# STM32MP21_CM33 register map
File version: 0.4
CPU: CM33 r0p1, little endian, MPU, FPU, vendor SysTick, 8 interrupt priority bits
Registers are 32-bit, read-write, reset 0x0 unless marked. A register's access mark holds for its fields unless they carry their own. Offsets are from the block's base; [hi:lo] are bit positions.

## TIM6 — TIM6 address block description
Base 0x40040000
Same registers: TIM6_S 0x50040000
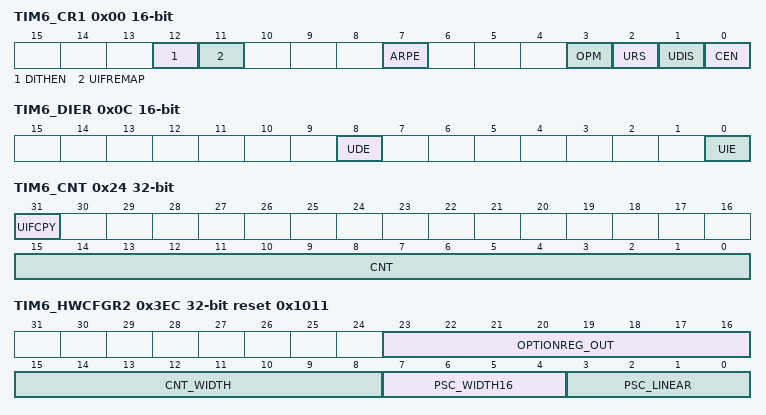
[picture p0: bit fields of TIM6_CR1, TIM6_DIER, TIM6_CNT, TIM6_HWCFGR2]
0x00 TIM6_CR1 16-bit — TIM6 control register 1
  [12] DITHEN — Dithering enable
    0=Dithering disabled; 1=Dithering enabled
  [11] UIFREMAP — UIF status bit remapping
    0=No remapping; 1=Remapping enabled
  [7] ARPE — Auto-reload preload enable
    0=TIMx_ARR register is not buffered; 1=TIMx_ARR register is buffered
  [3] OPM — One-pulse mode
    0=Counter is not stopped at update event; 1=Counter stops counting at the next update event (clearing the CEN bit)
  [2] URS — Update request source
    0=Any of the following events generates an update interrupt or DMA request if enabled; 1=Only counter overflow/underflow generates an update interrupt or DMA request if enabled
  [1] UDIS — Update disable
    0=UEV enabled; 1=UEV disabled
  [0] CEN — Counter enable
    0=Counter disabled; 1=Counter enabled
0x04 TIM6_CR2 16-bit — TIM6 control register 2
  [6:4] MMS — Master mode selection
    0=Reset - the UG bit from the TIMx_EGR register is used as a trigger output (tim_trgo); 1=Enable - the Counter enable signal, tim_cnt_en, is used as a trigger output (tim_trgo); 2=Update - The update event is selected as a trigger output (tim_trgo)
0x0C TIM6_DIER 16-bit — TIM6 DMA/Interrupt enable register
  [8] UDE — Update DMA request enable
    0=Update DMA request disabled; 1=Update DMA request enabled
  [0] UIE — Update interrupt enable
    0=Update interrupt disabled; 1=Update interrupt enabled
0x10 TIM6_SR 16-bit — TIM6 status register
  [0] UIF — Update interrupt flag
    0=No update occurred; 1=Update interrupt pending
0x14 TIM6_EGR 16-bit wo — TIM6 event generation register
  [0] UG — Update generation
    0=No action; 1=Re-initializes the timer counter and generates an update of the registers
0x24 TIM6_CNT — TIM6 counter
  [31] UIFCPY ro — UIF copy
  [15:0] CNT — Counter value
0x28 TIM6_PSC 16-bit — TIM6 prescaler
  [15:0] PSC — Prescaler value
0x2C TIM6_ARR reset 0xFFFF — TIM6 auto-reload register
  [19:0] ARR — Auto-reload value
0x3EC TIM6_HWCFGR2 ro reset 0x1011 — TIM6 hardware configuration 2 register
  [23:16] OPTIONREG_OUT — Option register number (0 to 16).
  [15:8] CNT_WIDTH — Counter width
    8=8-bits; 16=16-bits; 32=32-bits
  [7:4] PSC_WIDTH16 — Prescaler width
    0=7 (by power of 2) /8 (linear) -bit counter; 1=15 (by power of 2) /16 (linear) -bit counter
  [3:0] PSC_LINEAR — Prescaler linear
    0=prescaler by power of 2 (division by 1, 2, 4, 8; 1=prescaler is linear (division by 1, 2, 3, 4, 5
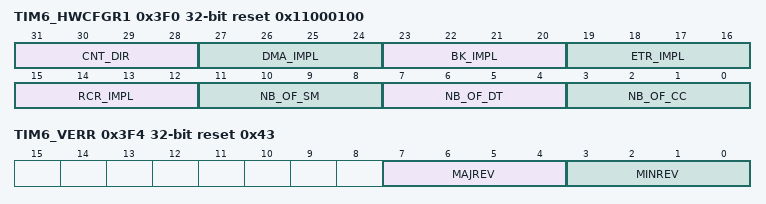
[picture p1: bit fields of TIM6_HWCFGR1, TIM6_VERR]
0x3F0 TIM6_HWCFGR1 ro reset 0x11000100 — TIM6 hardware configuration 1 register
  [31:28] CNT_DIR — Counter direction
    0=Down-counter only; 1=Up-counter only; 2=Up/Down counter allowing center-aligned mode
  [27:24] DMA_IMPL — DMA features implementation
    0=DMA requests are not possible; 1=Single DMA requests possible; 2=All DMA features implemented
  [23:20] BK_IMPL — Break circuit implementation
    0=no break implemented; 1=break1 implemented without filter (tim_brk + tim_sys_brk connected); 2=break1 implemented with filter (tim_brk + tim_sys_brk connected); 3=break 1 and 2 implemented (tim_brk + tim_sys_brk + brk2)
  [19:16] ETR_IMPL — External trigger implementation
    0=External trigger circuit not implemented, tim_ocrefx cleared by tim_ocref_clr input; 1=External trigger circuit implemented, tim_ocrefx cleared by tim_ocref_clr input; 2=External trigger circuit implemented, tim_ocrefx cleared by tim_etrf signal; 3=External trigger circuit implemented, tim_ocrefx cleared by tim_ocref_clr or tim_etrf (1 control bit OCCS added in GPT_SMCR)
  [15:12] RCR_IMPL — Repetition counter implementation
    0=repetition counter not implemented; 1=8-bit repetition counter implemented; 2=16-bit repetition counter implemented
  [11:8] NB_OF_SM — Number of synchronization module
    0=synchronization module not implemented; 1=1 synchronization module implemented
  [7:4] NB_OF_DT — Number of complementary outputs and dead-time generators
  [3:0] NB_OF_CC — Number of capture / compare channel
    0=no capture/compare channel implemented; 1=only CC1 channel is implemented; 2=CC1 and CC2 channels are implemented; 3=CC1, CC2 and CC3 channels are implemented; 4=CC1, CC2, CC3 and CC4 channels are implemented; 5=CC1, CC2, CC3, CC4 and CC5 channels are implemented; 6=CC1, CC2, CC3, CC4, CC5 and CC6 channels are implemented
0x3F4 TIM6_VERR ro reset 0x43 — TIM6 IP version register
  [7:4] MAJREV — Major revision number.
  [3:0] MINREV — Minor revision number.
0x3F8 TIM6_IPIDR ro reset 0x120002 — TIM6 IP identification register
  [31:0] ID — IP identification code.
0x3FC TIM6_SIDR ro reset 0xA3C5DD01 — TIM6 size ID register
  [31:0] SID — Offset in KB of the ID register base address from the IP base address.
    1=1KB offset

## TIM7 — TIM7 address block description
Base 0x40050000
Same registers: TIM7_S 0x50050000
Registers as TIM6 (with TIM6 read as TIM7).
